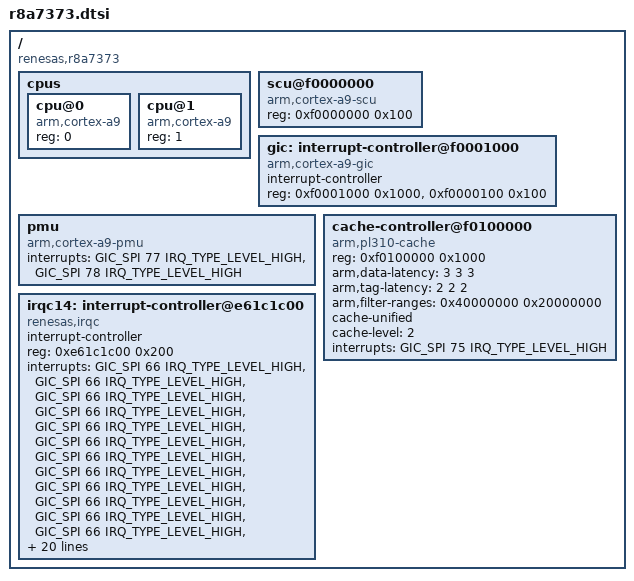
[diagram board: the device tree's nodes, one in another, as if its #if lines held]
/*
 * Device Tree Source for the r8a7373 SoC
 *
 * Copyright (C) 2013 Renesas Mobile
 *
 * This file is licensed under the terms of the GNU General Public License
 * version 2.  This program is licensed "as is" without any warranty of any
 * kind, whether express or implied.
 */

#include "u2-common.dtsi"

/{
	compatible = "renesas,r8a7373";

	cpus {
		#address-cells = <1>;
		#size-cells = <0>;

		cpu@0 {
			device_type = "cpu";
			compatible = "arm,cortex-a9";
			reg = <0>;
		};

		cpu@1 {
			device_type = "cpu";
			compatible = "arm,cortex-a9";
			reg = <1>;
		};
	};

	scu@f0000000 {
		compatible = "arm,cortex-a9-scu";
		reg = <0xf0000000 0x100>;
	};

	gic: interrupt-controller@f0001000 {
		compatible = "arm,cortex-a9-gic";
		interrupt-controller;
		reg = <0xf0001000 0x1000>,
		      <0xf0000100 0x100>;
		#interrupt-cells = <3>;
	};

	pmu {
		compatible = "arm,cortex-a9-pmu";
		interrupts = <GIC_SPI 77 IRQ_TYPE_LEVEL_HIGH>,
			     <GIC_SPI 78 IRQ_TYPE_LEVEL_HIGH>;
	};

	cache-controller@f0100000 {
		compatible = "arm,pl310-cache";
		reg = <0xf0100000 0x1000>;
		arm,data-latency = <3 3 3>;
		arm,tag-latency = <2 2 2>;
		arm,filter-ranges = <0x40000000 0x20000000>;
		cache-unified;
		cache-level = <2>;
		interrupts = <GIC_SPI 75 IRQ_TYPE_LEVEL_HIGH>;
	};

#ifdef USE_SENSOR_FRAMEWORK /* Save space - we don't currently use this */
	/* From sensor framework */
	irqc14: interrupt-controller@e61c1c00 {
		compatible = "renesas,irqc";
		#interrupt-cells = <2>;
		interrupt-controller;
		reg = <0xe61c1c00 0x200>;
		interrupts = <GIC_SPI 66 IRQ_TYPE_LEVEL_HIGH>,
			     <GIC_SPI 66 IRQ_TYPE_LEVEL_HIGH>,
			     <GIC_SPI 66 IRQ_TYPE_LEVEL_HIGH>,
			     <GIC_SPI 66 IRQ_TYPE_LEVEL_HIGH>,
			     <GIC_SPI 66 IRQ_TYPE_LEVEL_HIGH>,
			     <GIC_SPI 66 IRQ_TYPE_LEVEL_HIGH>,
			     <GIC_SPI 66 IRQ_TYPE_LEVEL_HIGH>,
			     <GIC_SPI 66 IRQ_TYPE_LEVEL_HIGH>,
			     <GIC_SPI 66 IRQ_TYPE_LEVEL_HIGH>,
			     <GIC_SPI 66 IRQ_TYPE_LEVEL_HIGH>,
			     <GIC_SPI 66 IRQ_TYPE_LEVEL_HIGH>,
			     <GIC_SPI 66 IRQ_TYPE_LEVEL_HIGH>,
			     <GIC_SPI 66 IRQ_TYPE_LEVEL_HIGH>,
			     <GIC_SPI 66 IRQ_TYPE_LEVEL_HIGH>,
			     <GIC_SPI 66 IRQ_TYPE_LEVEL_HIGH>,
			     <GIC_SPI 66 IRQ_TYPE_LEVEL_HIGH>,
			     <GIC_SPI 66 IRQ_TYPE_LEVEL_HIGH>,
			     <GIC_SPI 66 IRQ_TYPE_LEVEL_HIGH>,
			     <GIC_SPI 66 IRQ_TYPE_LEVEL_HIGH>,
			     <GIC_SPI 66 IRQ_TYPE_LEVEL_HIGH>,
			     <GIC_SPI 66 IRQ_TYPE_LEVEL_HIGH>,
			     <GIC_SPI 66 IRQ_TYPE_LEVEL_HIGH>,
			     <GIC_SPI 66 IRQ_TYPE_LEVEL_HIGH>,
			     <GIC_SPI 66 IRQ_TYPE_LEVEL_HIGH>,
			     <GIC_SPI 66 IRQ_TYPE_LEVEL_HIGH>,
			     <GIC_SPI 66 IRQ_TYPE_LEVEL_HIGH>,
			     <GIC_SPI 66 IRQ_TYPE_LEVEL_HIGH>,
			     <GIC_SPI 66 IRQ_TYPE_LEVEL_HIGH>,
			     <GIC_SPI 66 IRQ_TYPE_LEVEL_HIGH>,
			     <GIC_SPI 66 IRQ_TYPE_LEVEL_HIGH>,
			     <GIC_SPI 66 IRQ_TYPE_LEVEL_HIGH>,
			     <GIC_SPI 66 IRQ_TYPE_LEVEL_HIGH>;
	};
#endif
};
